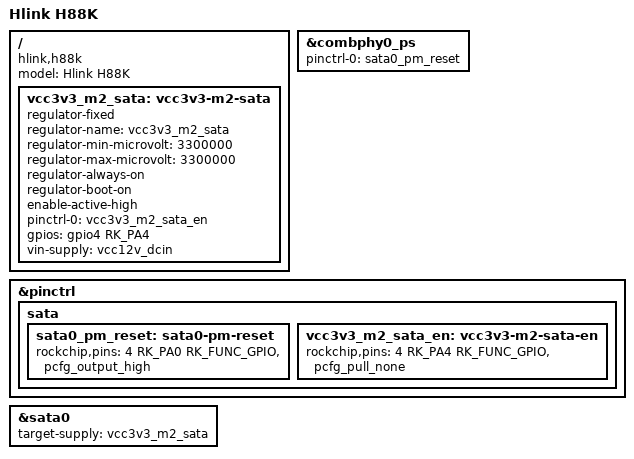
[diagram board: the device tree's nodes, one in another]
// SPDX-License-Identifier: (GPL-2.0+ OR MIT)
// Copyright (c) 2024 Flippy <flippy@sina.com>

/dts-v1/;

#include "rk3588-hlink.dtsi"

/ {
	model = "Hlink H88K";
	compatible = "hlink,h88k", "rockchip,rk3588";

	vcc3v3_m2_sata: vcc3v3-m2-sata {
		compatible = "regulator-fixed";
		regulator-name = "vcc3v3_m2_sata";
		regulator-min-microvolt = <3300000>;
		regulator-max-microvolt = <3300000>;
		regulator-always-on;
		regulator-boot-on;
		enable-active-high;
		pinctrl-names = "default";
		pinctrl-0 = <&vcc3v3_m2_sata_en>;
		gpios = <&gpio4 RK_PA4 GPIO_ACTIVE_HIGH>;
		vin-supply = <&vcc12v_dcin>;
	};
};


&combphy0_ps {
	status = "okay";
	pinctrl-names = "default";
	pinctrl-0 = <&sata0_pm_reset>;
};

&pinctrl {
	sata {
		sata0_pm_reset: sata0-pm-reset {
			rockchip,pins = <4 RK_PA0 RK_FUNC_GPIO &pcfg_output_high>;
		};

		vcc3v3_m2_sata_en: vcc3v3-m2-sata-en {
			rockchip,pins = <4 RK_PA4 RK_FUNC_GPIO &pcfg_pull_none>;
		};
	};
};

/* phy is combphy0_ps */
&sata0 {
	status = "okay";
	target-supply = <&vcc3v3_m2_sata>;
};
